# STM32H743 register map
File version: 2.4
CPU: CM7 r0p1, little endian, MPU, FPU, 4 interrupt priority bits
Registers are 32-bit, read-write, reset 0x0 unless marked. A register's access mark holds for its fields unless they carry their own. Offsets are from the block's base; [hi:lo] are bit positions; 'fields as' and 'values as' point back to an identical list.

## LTDC — LCD-TFT 控制器
Base 0x50001000
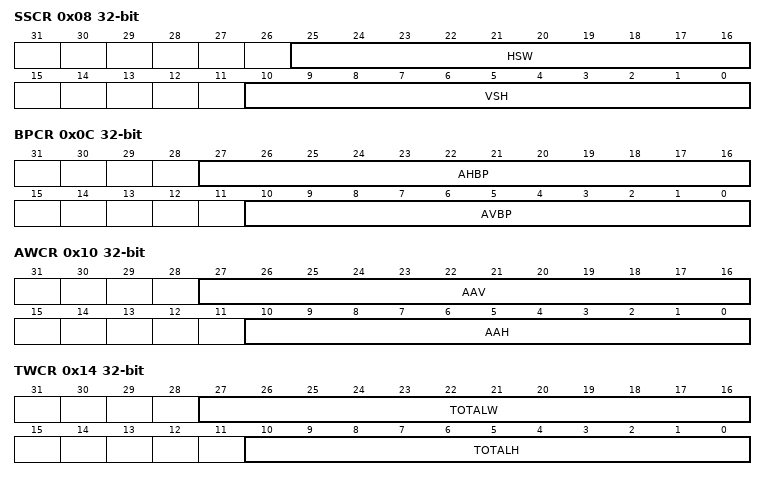
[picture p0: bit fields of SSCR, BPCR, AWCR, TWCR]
0x08 SSCR — 同步信号尺寸配置寄存器
  [25:16] HSW — 水平同步宽度（以像素时钟周期为单位）
  [10:0] VSH — 垂直同步高度（以水平行扫描线为单位）
0x0C BPCR — 后沿配置寄存器
  [27:16] AHBP — 累计水平后沿（以像素时钟周期为单位）
  [10:0] AVBP — 累计垂直后沿（以水平行扫描线为单位）
0x10 AWCR — 有效宽度配置寄存器
  [27:16] AAV — 累积有效宽度（以像素时钟周期为单位）
  [10:0] AAH — 累计有效高度（以水平行扫描线为单位）
0x14 TWCR — 总宽度配置寄存器
  [27:16] TOTALW — 总宽度（以像素时钟周期为单位）
  [10:0] TOTALH — 总高度（以水平行扫描线为单位）
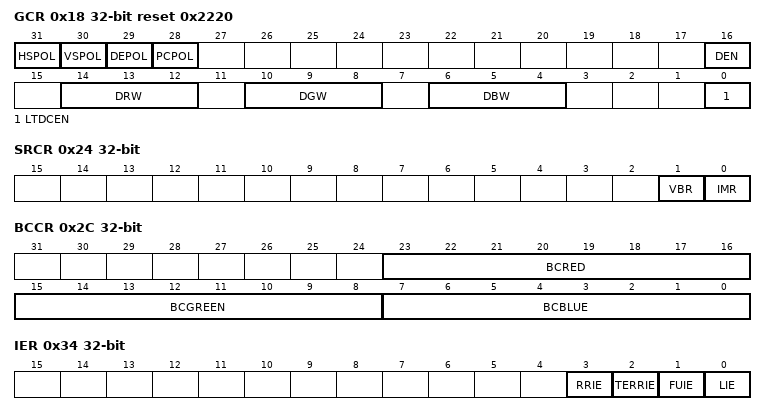
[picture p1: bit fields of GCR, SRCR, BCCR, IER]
0x18 GCR access per field reset 0x2220 — 全局控制寄存器
  [31] HSPOL rw — 水平同步极性
  [30] VSPOL rw — 垂直同步极性
  [29] DEPOL rw — 数据使能极性
  [28] PCPOL rw — 像素时钟极性
  [16] DEN rw — 抖动使能
  [14:12] DRW ro — 红色抖动位宽
  [10:8] DGW ro — 绿色抖动位宽
  [6:4] DBW ro — 蓝色抖动位宽
  [0] LTDCEN rw — LCD-TFT 控制器使能位
0x24 SRCR — 影子寄存器重载配置寄存器
  [1] VBR — 垂直消隐期重载
  [0] IMR — 立即重载
0x2C BCCR — 背景颜色配置寄存器
  [23:16] BCRED — 背景颜色红色分量值
  [15:8] BCGREEN — 背景颜色绿色分量值
  [7:0] BCBLUE — 背景颜色蓝色分量值
0x34 IER — 中断使能寄存器
  [3] RRIE — 寄存器重载中断使能
  [2] TERRIE — 传输错误中断使能
  [1] FUIE — FIFO 欠载中断使能
  [0] LIE — 行中断使能
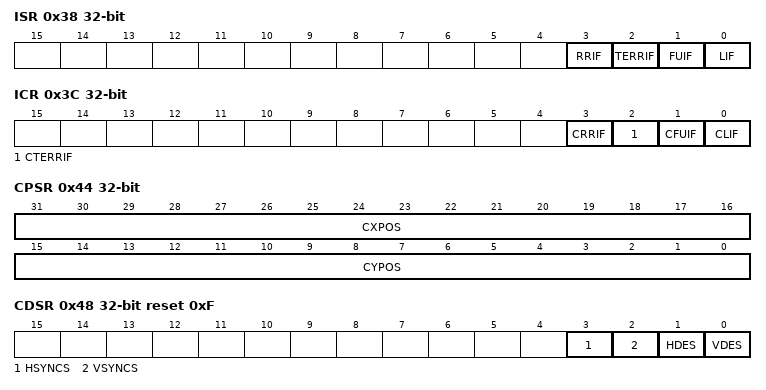
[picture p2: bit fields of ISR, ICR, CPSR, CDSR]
0x38 ISR ro — 中断状态寄存器
  [3] RRIF — 寄存器重载中断标志
  [2] TERRIF — 传输错误中断标志
  [1] FUIF — FIFO 欠载中断标志
  [0] LIF — 行中断标志
0x3C ICR wo — 中断清除寄存器
  [3] CRRIF — 清除寄存器重载中断标志
  [2] CTERRIF — 清除传输错误中断标志
  [1] CFUIF — 清除 FIFO 欠载中断标志
  [0] CLIF — 清除行中断标志
0x40 LIPCR — 行中断位置配置寄存器
  [10:0] LIPOS — 行中断位置
0x44 CPSR ro — 当前位置状态寄存器
  [31:16] CXPOS — 当前 X 坐标（水平位置）
  [15:0] CYPOS — 当前 Y 坐标（垂直位置）
0x48 CDSR ro reset 0xF — 当前显示状态寄存器
  [3] HSYNCS — 水平同步显示状态
  [2] VSYNCS — 垂直同步显示状态
  [1] HDES — 水平数据使能显示状态
  [0] VDES — 垂直数据使能显示状态
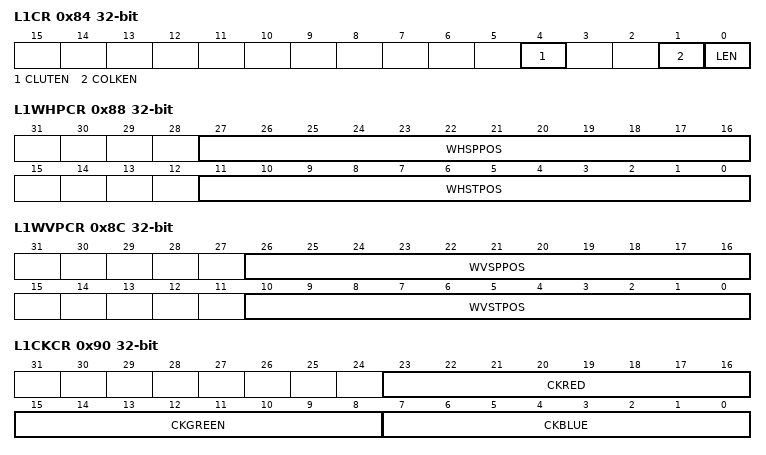
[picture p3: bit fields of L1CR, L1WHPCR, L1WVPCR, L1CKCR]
0x84 L1CR — 层控制寄存器
  [4] CLUTEN — 颜色查找表使能
  [1] COLKEN — 色键使能
  [0] LEN — 层使能
0x88 L1WHPCR — 层窗口水平位置配置寄存器
  [27:16] WHSPPOS — 窗口水平结束位置
  [11:0] WHSTPOS — 窗口水平起始位置
0x8C L1WVPCR — 层窗口垂直位置配置寄存器
  [26:16] WVSPPOS — 窗口垂直结束位置
  [10:0] WVSTPOS — 窗口垂直起始位置
0x90 L1CKCR — 层色键配置寄存器
  [23:16] CKRED — 色键红色分量值
  [15:8] CKGREEN — 色键绿色分量值
  [7:0] CKBLUE — 色键蓝色分量值
0x94 L1PFCR — 层像素格式配置寄存器
  [2:0] PF — 像素格式
0x98 L1CACR — 层常量 Alpha 配置寄存器
  [7:0] CONSTA — 常量 Alpha 值
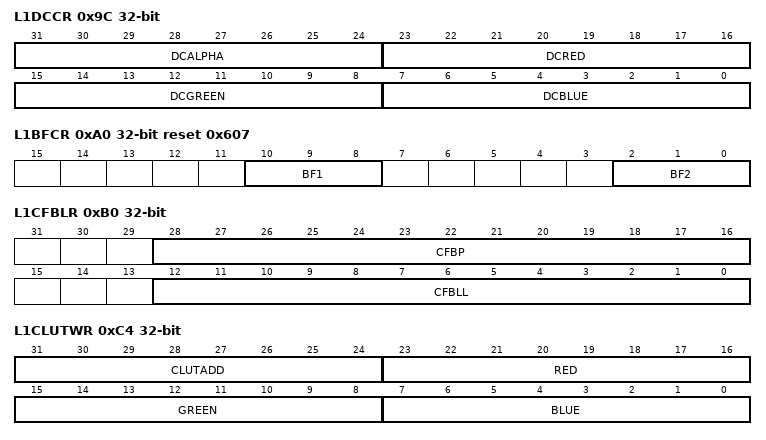
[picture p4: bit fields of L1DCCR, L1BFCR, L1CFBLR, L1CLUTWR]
0x9C L1DCCR — 层默认颜色配置寄存器
  [31:24] DCALPHA — 默认颜色 Alpha 值
  [23:16] DCRED — 默认颜色红色分量值
  [15:8] DCGREEN — 默认颜色绿色分量值
  [7:0] DCBLUE — 默认颜色蓝色分量值
0xA0 L1BFCR reset 0x607 — 层混合因子配置寄存器
  [10:8] BF1 — 混合因子 1
  [2:0] BF2 — 混合因子 2
0xAC L1CFBAR — 层颜色帧缓冲区地址寄存器
  [31:0] CFBADD — 颜色帧缓冲区起始地址
0xB0 L1CFBLR — 层颜色帧缓冲区长度寄存器
  [28:16] CFBP — 颜色帧缓冲区行跨度（以字节为单位）
  [12:0] CFBLL — 颜色帧缓冲区行长度
0xB4 L1CFBLNR — 层颜色帧缓冲区行号寄存器
  [10:0] CFBLNBR — 帧缓冲区行号
0xC4 L1CLUTWR wo — 层 CLUT 写寄存器
  [31:24] CLUTADD — CLUT 地址
  [23:16] RED — 红色分量值
  [15:8] GREEN — 绿色分量值
  [7:0] BLUE — 蓝色分量值
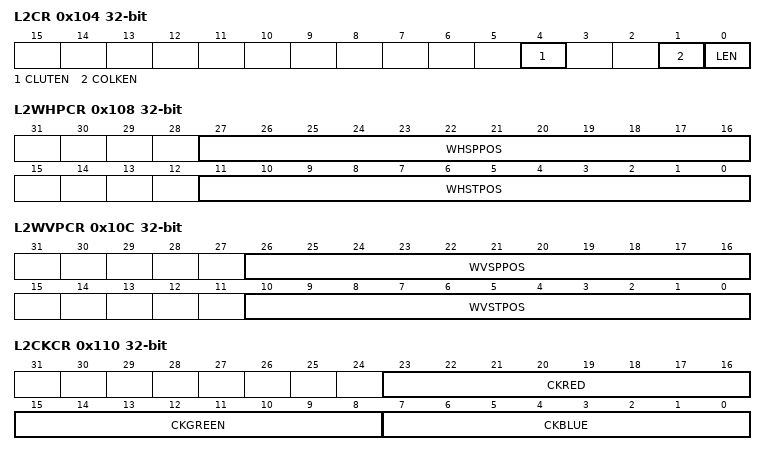
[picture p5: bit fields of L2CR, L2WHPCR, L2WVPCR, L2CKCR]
0x104 L2CR — 层控制寄存器
  [4] CLUTEN — 颜色查找表使能
  [1] COLKEN — 色键使能
  [0] LEN — 层使能
0x108 L2WHPCR — 层窗口水平位置配置寄存器
  [27:16] WHSPPOS — 窗口水平结束位置
  [11:0] WHSTPOS — 窗口水平起始位置
0x10C L2WVPCR — 层窗口垂直位置配置寄存器
  [26:16] WVSPPOS — 窗口垂直结束位置
  [10:0] WVSTPOS — 窗口垂直起始位置
0x110 L2CKCR — 层色键配置寄存器
  fields as L1CKCR
0x114 L2PFCR — 层像素格式配置寄存器
  [2:0] PF — 像素格式
0x118 L2CACR — 层常量 Alpha 配置寄存器
  [7:0] CONSTA — 常量 Alpha 值
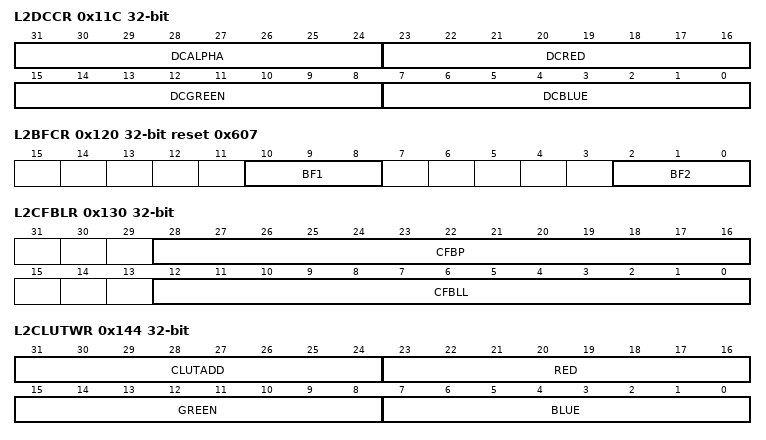
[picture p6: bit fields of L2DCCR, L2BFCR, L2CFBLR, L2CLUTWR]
0x11C L2DCCR — 层默认颜色配置寄存器
  fields as L1DCCR
0x120 L2BFCR reset 0x607 — 层混合因子配置寄存器
  [10:8] BF1 — 混合因子 1
  [2:0] BF2 — 混合因子 2
0x12C L2CFBAR — 层颜色帧缓冲区地址寄存器
  [31:0] CFBADD — 颜色帧缓冲区起始地址
0x130 L2CFBLR — 层颜色帧缓冲区长度寄存器
  [28:16] CFBP — 颜色帧缓冲区行跨度（以字节为单位）
  [12:0] CFBLL — 颜色帧缓冲区行长度
0x134 L2CFBLNR — 层颜色帧缓冲区行号寄存器
  [10:0] CFBLNBR — 帧缓冲区行号
0x144 L2CLUTWR wo — 层 CLUT 写寄存器
  fields as L1CLUTWR

## SPDIFRX — S/PDIF 接收器接口
Base 0x40004000
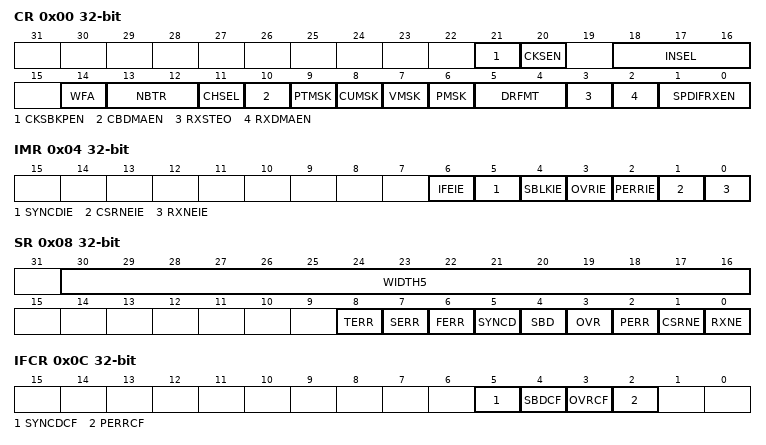
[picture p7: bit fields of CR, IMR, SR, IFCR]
0x00 CR — 控制寄存器
  [21] CKSBKPEN — 备用符号时钟使能
  [20] CKSEN — 符号时钟使能
  [18:16] INSEL — 输入选择
  [14] WFA — 等待活动
  [13:12] NBTR — 同步阶段最大允许重试次数
  [11] CHSEL — 通道选择
  [10] CBDMAEN — 控制流控制缓冲区 DMA 使能
  [9] PTMSK — 前导码类型位屏蔽
  [8] CUMSK — 通道状态位和用户位屏蔽
  [7] VMSK — 有效位屏蔽
  [6] PMSK — 奇偶校验错误位屏蔽
  [5:4] DRFMT — 接收数据格式
  [3] RXSTEO — 立体声模式
  [2] RXDMAEN — 数据流接收 DMA 使能
  [1:0] SPDIFRXEN — 外设模块使能
0x04 IMR — 中断屏蔽寄存器
  [6] IFEIE — 串行接口错误中断使能
  [5] SYNCDIE — 同步完成中断使能
  [4] SBLKIE — 同步块检测中断使能
  [3] OVRIE — 溢出错误中断使能
  [2] PERRIE — 奇偶校验错误中断使能
  [1] CSRNEIE — 控制缓冲区就绪中断使能
  [0] RXNEIE — 接收数据寄存器非空中断使能
0x08 SR ro — 状态寄存器
  [30:16] WIDTH5 — 以 SPDIF_CLK 计数的 5 个符号持续时间
  [8] TERR — 超时错误
  [7] SERR — 同步错误
  [6] FERR — 帧错误
  [5] SYNCD — 同步完成
  [4] SBD — 检测到同步块
  [3] OVR — 溢出错误
  [2] PERR — 奇偶校验错误
  [1] CSRNE — 控制缓冲寄存器非空
  [0] RXNE — 接收数据寄存器非空
0x0C IFCR wo — 中断标志清除寄存器
  [5] SYNCDCF — 清除同步完成标志
  [4] SBDCF — 清除同步块检测标志
  [3] OVRCF — 清除溢出错误标志
  [2] PERRCF — 清除奇偶校验错误标志
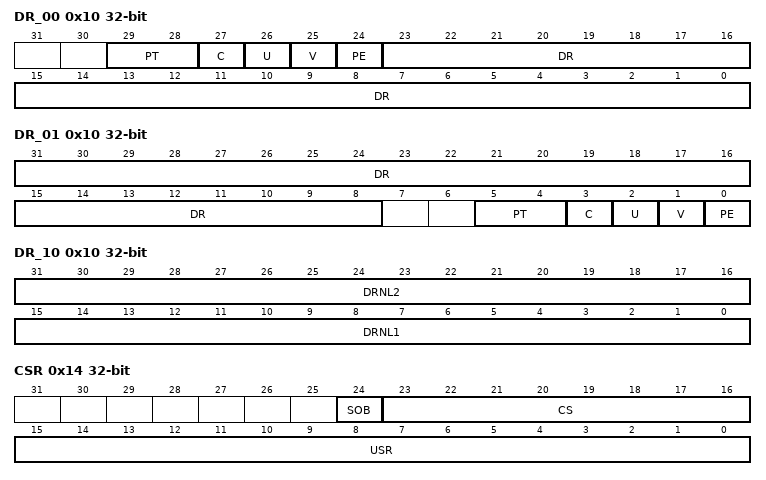
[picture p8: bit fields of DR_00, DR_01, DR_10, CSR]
0x10 DR_00 ro — 数据输入寄存器
  [29:28] PT — 前导码类型
  [27] C — 通道状态位
  [26] U — 用户位
  [25] V — 有效位
  [24] PE — 奇偶校验错误位
  [23:0] DR — 奇偶校验错误位
0x10 DR_01 ro (alternate view of DR_00) — 数据输入寄存器
  [31:8] DR — 数据值
  [5:4] PT — 前导码类型
  [3] C — 通道状态位
  [2] U — 用户位
  [1] V — 有效位
  [0] PE — 奇偶校验错误位
0x10 DR_10 ro (alternate view of DR_00) — 数据输入寄存器
  [31:16] DRNL2 — 数据值
  [15:0] DRNL1 — 数据值
0x14 CSR ro — 通道状态寄存器
  [24] SOB — 块起始
  [23:16] CS — 通道 A 状态信息
  [15:0] USR — 用户数据信息
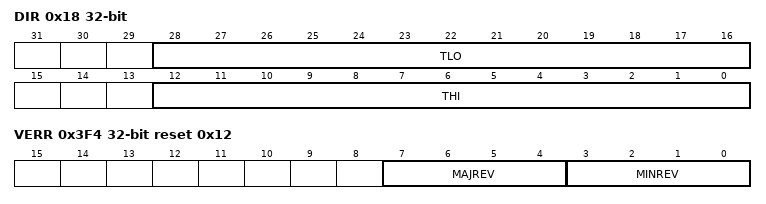
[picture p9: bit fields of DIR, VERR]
0x18 DIR ro — 调试信息寄存器
  [28:16] TLO — 低阈值
  [12:0] THI — 高阈值
0x3F4 VERR ro reset 0x12 — SPDIFRX 版本寄存器
  [7:4] MAJREV — 主版本号
  [3:0] MINREV — 次版本号
0x3F8 IDR ro reset 0x130041 — SPDIFRX 识别寄存器
  [31:0] ID — SPDIFRX 标识符
0x3FC SIDR ro reset 0xA3C5DD01 — SPDIFRX 大小识别寄存器
  [31:0] SID — 大小识别
